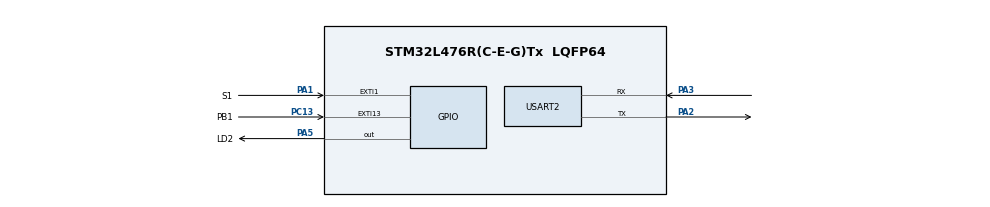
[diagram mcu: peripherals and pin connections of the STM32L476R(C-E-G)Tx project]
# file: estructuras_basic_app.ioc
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Mcu.Family=STM32L4
Mcu.Name=STM32L476R(C-E-G)Tx
Mcu.Package=LQFP64
NVIC.EXTI15_10_IRQn=true\:0\:0\:false\:false\:true\:true\:true\:true
NVIC.EXTI1_IRQn=true\:0\:0\:false\:false\:true\:true\:true\:true
NVIC.PriorityGroup=NVIC_PRIORITYGROUP_4
PA1.GPIO_Label=S1
PA1.GPIO_ModeDefaultEXTI=GPIO_MODE_IT_FALLING
PA1.Signal=GPXTI1
PA2.Mode=Asynchronous
PA2.Signal=USART2_TX
PA3.Mode=Asynchronous
PA3.Signal=USART2_RX
PA5.GPIO_Label=LD2
PA5.PinState=GPIO_PIN_RESET
PA5.Signal=GPIO_Output
PC13.GPIO_Label=PB1
PC13.GPIO_ModeDefaultEXTI=GPIO_MODE_IT_FALLING
PC13.Signal=GPXTI13
ProjectManager.HeapSize=0x200
ProjectManager.StackSize=0x400
ProjectManager.TargetToolchain=STM32CubeIDE
RCC.HSE_VALUE=8000000
RCC.HSI_VALUE=16000000
RCC.LSE_VALUE=32768
RCC.MSI_VALUE=4000000
RCC.VCOOutputFreq_Value=32000000
USART2.VirtualMode-Asynchronous=VM_ASYNC
board=custom

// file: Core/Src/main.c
/* USER CODE BEGIN Header */
/**
  ******************************************************************************
  * @file           : main.c
  * @brief          : Main program body
  ******************************************************************************
  * @attention
  *
  * Copyright (c) 2024 STMicroelectronics.
  * All rights reserved.
  *
  * This software is licensed under terms that can be found in the LICENSE file
  * in the root directory of this software component.
  * If no LICENSE file comes with this software, it is provided AS-IS.
  *
  ******************************************************************************
  */
/* USER CODE END Header */
#include "main.h"

UART_HandleTypeDef huart2;

void SystemClock_Config(void);
static void MX_GPIO_Init(void);
static void MX_USART2_UART_Init(void);

/* USER CODE BEGIN 0 */
void HAL_GPIO_EXTI_Callback(uint16_t GPIO_Pin)
{
  /* Prevent unused argument(s) compilation warning */
  UNUSED(GPIO_Pin);

  if (GPIO_Pin == GPIO_PIN_13){//PC13(PB1)
	  HAL_GPIO_TogglePin(LD2_GPIO_Port,LD2_Pin);
	  HAL_UART_Transmit(&huart2,"PB1\r\n",5,10);
  }else if (GPIO_Pin == GPIO_PIN_1){
	  HAL_GPIO_WritePin(LD2_GPIO_Port,LD2_Pin,0);
	  for(uint16_t counter = 0; counter < 0xEFFF; counter++){}
	  HAL_GPIO_WritePin(LD2_GPIO_Port,LD2_Pin,1);}
}
/* USER CODE END 0 */

int main(void)
{

  /* MCU Configuration--------------------------------------------------------*/

  /* Reset of all peripherals, Initializes the Flash interface and the Systick. */
  HAL_Init();

  /* Configure the system clock */
  SystemClock_Config();

  /* Initialize all configured peripherals */
  MX_GPIO_Init();
  MX_USART2_UART_Init();
  /* USER CODE BEGIN 2 */
  HAL_UART_Transmit(&huart2,"Hello,world\r\n",13,10);
  /* USER CODE END 2 */

  /* Infinite loop */
  /* USER CODE BEGIN WHILE */
//  uint32_t timeout_tick;
  while (1)
  {
//	  if(HAL_GPIO_ReadPin(PB1_GPIO_Port, GPIO_PIN_13)==0){
//		  HAL_GPIO_WritePin(LD2_GPIO_Port, GPIO_PIN_5, 1);
//	  } else{
//		  HAL_GPIO_WritePin(LD2_GPIO_Port, GPIO_PIN_5, 0);
//	  }
//	  if(timeout_tick<HAL_GetTick()){
//		  timeout_tick=HAL_GetTick()+500;
//		  GPIOA->ODR^=0x01<<5;
	  }
    /* USER CODE END WHILE */

}

void SystemClock_Config(void)
{
  RCC_OscInitTypeDef RCC_OscInitStruct = {0};
  RCC_ClkInitTypeDef RCC_ClkInitStruct = {0};

  /** Configure the main internal regulator output voltage
  */
  if (HAL_PWREx_ControlVoltageScaling(PWR_REGULATOR_VOLTAGE_SCALE1) != HAL_OK)
  {
    Error_Handler();
  }

  /** Initializes the RCC Oscillators according to the specified parameters
  * in the RCC_OscInitTypeDef structure.
  */
  RCC_OscInitStruct.OscillatorType = RCC_OSCILLATORTYPE_MSI;
  RCC_OscInitStruct.MSIState = RCC_MSI_ON;
  RCC_OscInitStruct.MSICalibrationValue = 0;
  RCC_OscInitStruct.MSIClockRange = RCC_MSIRANGE_6;
  RCC_OscInitStruct.PLL.PLLState = RCC_PLL_NONE;
  if (HAL_RCC_OscConfig(&RCC_OscInitStruct) != HAL_OK)
  {
    Error_Handler();
  }

  /** Initializes the CPU, AHB and APB buses clocks
  */
  RCC_ClkInitStruct.ClockType = RCC_CLOCKTYPE_HCLK|RCC_CLOCKTYPE_SYSCLK
                              |RCC_CLOCKTYPE_PCLK1|RCC_CLOCKTYPE_PCLK2;
  RCC_ClkInitStruct.SYSCLKSource = RCC_SYSCLKSOURCE_MSI;
  RCC_ClkInitStruct.AHBCLKDivider = RCC_SYSCLK_DIV1;
  RCC_ClkInitStruct.APB1CLKDivider = RCC_HCLK_DIV1;
  RCC_ClkInitStruct.APB2CLKDivider = RCC_HCLK_DIV1;

  if (HAL_RCC_ClockConfig(&RCC_ClkInitStruct, FLASH_LATENCY_0) != HAL_OK)
  {
    Error_Handler();
  }
}

static void MX_USART2_UART_Init(void)
{

  huart2.Instance = USART2;
  huart2.Init.BaudRate = 115200;
  huart2.Init.WordLength = UART_WORDLENGTH_8B;
  huart2.Init.StopBits = UART_STOPBITS_1;
  huart2.Init.Parity = UART_PARITY_NONE;
  huart2.Init.Mode = UART_MODE_TX_RX;
  huart2.Init.HwFlowCtl = UART_HWCONTROL_NONE;
  huart2.Init.OverSampling = UART_OVERSAMPLING_16;
  huart2.Init.OneBitSampling = UART_ONE_BIT_SAMPLE_DISABLE;
  huart2.AdvancedInit.AdvFeatureInit = UART_ADVFEATURE_NO_INIT;
  if (HAL_UART_Init(&huart2) != HAL_OK)
  {
    Error_Handler();
  }

}

static void MX_GPIO_Init(void)
{
  GPIO_InitTypeDef GPIO_InitStruct = {0};

  /* GPIO Ports Clock Enable */
  __HAL_RCC_GPIOC_CLK_ENABLE();
  __HAL_RCC_GPIOA_CLK_ENABLE();

  /*Configure GPIO pin Output Level */
  HAL_GPIO_WritePin(LD2_GPIO_Port, LD2_Pin, GPIO_PIN_RESET);

  /*Configure GPIO pin : PB1_Pin */
  GPIO_InitStruct.Pin = PB1_Pin;
  GPIO_InitStruct.Mode = GPIO_MODE_IT_FALLING;
  GPIO_InitStruct.Pull = GPIO_NOPULL;
  HAL_GPIO_Init(PB1_GPIO_Port, &GPIO_InitStruct);

  /*Configure GPIO pin : S1_Pin */
  GPIO_InitStruct.Pin = S1_Pin;
  GPIO_InitStruct.Mode = GPIO_MODE_IT_FALLING;
  GPIO_InitStruct.Pull = GPIO_NOPULL;
  HAL_GPIO_Init(S1_GPIO_Port, &GPIO_InitStruct);

  /*Configure GPIO pin : LD2_Pin */
  GPIO_InitStruct.Pin = LD2_Pin;
  GPIO_InitStruct.Mode = GPIO_MODE_OUTPUT_PP;
  GPIO_InitStruct.Pull = GPIO_NOPULL;
  GPIO_InitStruct.Speed = GPIO_SPEED_FREQ_LOW;
  HAL_GPIO_Init(LD2_GPIO_Port, &GPIO_InitStruct);

  /* EXTI interrupt init*/
  HAL_NVIC_SetPriority(EXTI1_IRQn, 0, 0);
  HAL_NVIC_EnableIRQ(EXTI1_IRQn);

  HAL_NVIC_SetPriority(EXTI15_10_IRQn, 0, 0);
  HAL_NVIC_EnableIRQ(EXTI15_10_IRQn);

}

void Error_Handler(void)
{
  __disable_irq();
  while (1)
  {
  }
}
